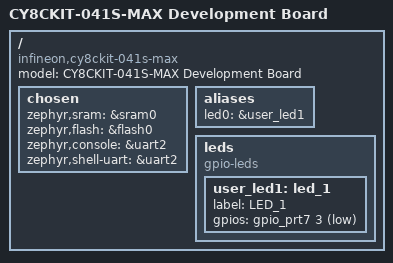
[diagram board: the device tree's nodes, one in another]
/*
 * Copyright (c) 2025 Infineon Technologies AG,
 * or an affiliate of Infineon Technologies AG.
 *
 * SPDX-License-Identifier: Apache-2.0
 */

/dts-v1/;
#include <arm/infineon/psoc4/mpns/cy8c4149azi_s598.dtsi>
#include <arm/infineon/psoc4/psoc4100smax/system_clocks.dtsi>

#include "cy8ckit_041s_max_common.dtsi"

/ {
	model = "CY8CKIT-041S-MAX Development Board";
	compatible = "infineon,cy8ckit-041s-max", "infineon,psoc4100smax";

	chosen {
		zephyr,sram = &sram0;
		zephyr,flash = &flash0;
		zephyr,console = &uart2;
		zephyr,shell-uart = &uart2;
	};

	aliases {
		led0 = &user_led1;
	};

	leds {
		compatible = "gpio-leds";
		status = "okay";

		user_led1: led_1 {
			label = "LED_1";
			gpios = <&gpio_prt7 3 GPIO_ACTIVE_LOW>;
		};
	};
};
